# DA1470x register map
Vendor: Dialog; Series: DA1470x; File version: 1.2
CPU: CM33 r0p2, little endian, MPU, FPU, DSP, VTOR, 4 interrupt priority bits
Registers are 32-bit, read-write, reset 0x0 unless marked. A register's access mark holds for its fields unless they carry their own. Offsets are from the block's base; [hi:lo] are bit positions.

## CRG_VSYS — CRG_VSYS registers
Base 0x50000B00
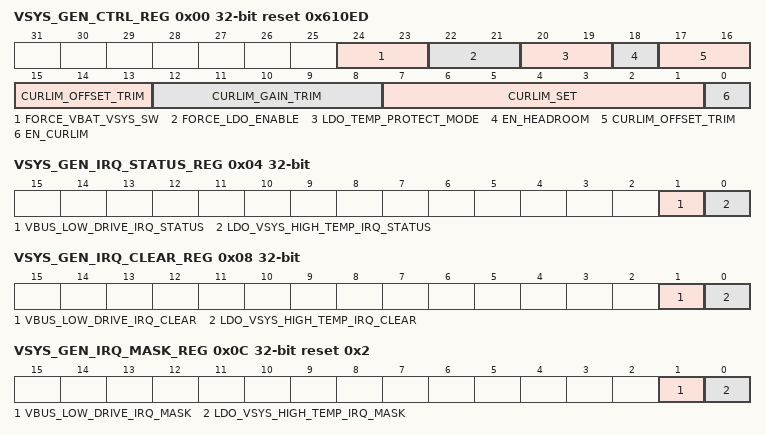
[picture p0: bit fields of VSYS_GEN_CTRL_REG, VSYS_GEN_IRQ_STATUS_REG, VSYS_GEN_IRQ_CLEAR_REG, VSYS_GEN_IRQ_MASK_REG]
0x00 VSYS_GEN_CTRL_REG reset 0x610ED
  [24:23] FORCE_VBAT_VSYS_SW — 0x0,0x1: VBAT_VSYS set to ideal diode 0x2: Forces VBAT_VSYS switch to be opened 0x3: Forces VBAT_VSYS switch to be closed
  [22:21] FORCE_LDO_ENABLE — 0x0,0x1: LDO VSYS will be enabled when COMP_VBUS_OK & COMP_VBUS_ABOVE_VSYS. 0x2: LDO_VSYS will be disabled regardless of VBUS state 0x3: LDO_VSYS will be enabled regardless of VBUS state
  [20:19] LDO_TEMP_PROTECT_MODE — 0x0: LDO_VSYS is muted (disabled) when temperature is too high, when temperature is back to operating conditions ldo is unmuted 0x1: LDO_VSYS is muted (disabled) when temperature is too high, LDO_VSYS_HIGH_TEMP_IRQ must be cleared to allow ldo to be unmuted. See VSYS_GEN_IRQ_CLEAR_REG. 0x2: LDO_VSYS is not muted (disabled) when temperature is too high 0x3: Force LDO_VSYS mute
  [18] EN_HEADROOM — Enables the voltage headroom loop in the LDO_VSYS.
  [17:13] CURLIM_OFFSET_TRIM — For adjusting the offset of the curlim range ( +/- 78 mA) 0x0 = maximum positive offset. 0x10 = minimal offset ( reset value). 0x1F = maximum negative offset.
  [12:8] CURLIM_GAIN_TRIM — For adjusting the gain of the curlim range ( +/- 20%) 0x0 = maximum gain. 0x10 = nominal gain ( reset value). 0x1F = minimum gain.
  [7:1] CURLIM_SET — Sets the level of the LDO_VSYS current limiter in 10 mA steps. It is reset when vbus is not plugged (COMP_VBUS_PLUGIN == 0). 0x0 = 1270 mA 0x1 = 1260 mA ... 0x76 = 90 mA ( reset value)
  [0] EN_CURLIM — Enables the current limiter in the LDO_VSYS
0x04 VSYS_GEN_IRQ_STATUS_REG
  [1] VBUS_LOW_DRIVE_IRQ_STATUS — Indicates vbus drive strength is not enough to keep vbus up with the set limit of ldo_vbus. Consider lowering CURLIM_SET in VSYS_GEN_CTRL_REG.
  [0] LDO_VSYS_HIGH_TEMP_IRQ_STATUS — Indicates that a high temperature has been detected at ldo_vsys
0x08 VSYS_GEN_IRQ_CLEAR_REG
  [1] VBUS_LOW_DRIVE_IRQ_CLEAR wo — Clears VBUS_LOW_DRIVE_IRQ
  [0] LDO_VSYS_HIGH_TEMP_IRQ_CLEAR wo — Clears LDO_VSYS_HIGH_TEMP_IRQ
0x0C VSYS_GEN_IRQ_MASK_REG reset 0x2
  [1] VBUS_LOW_DRIVE_IRQ_MASK — Masks VBUS_LOW_DRIVE_IRQ interrupt. It is reset when vbus is not plugged in (COMP_VBUS_PLUGIN == 0). This is because when vbus is just plugged in, it is likely to bounce; therefore IRQ is masked to avoid false triggering. Some time after vbus plugin, software might increase ldo_vsys current limit and should set this mask to 0 (after clearing IRQ).
  [0] LDO_VSYS_HIGH_TEMP_IRQ_MASK — Masks LDO_VSYS_HIGH_TEMP_IRQ interrupt

## DCDC — DCDC registers
Base 0x50000300
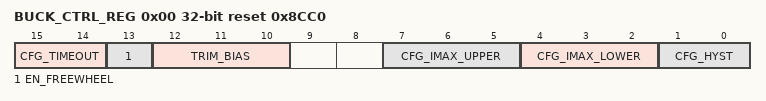
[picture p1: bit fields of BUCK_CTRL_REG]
0x00 BUCK_CTRL_REG reset 0x8CC0
  [15:14] CFG_TIMEOUT — Sets maximum switch on-time. 0x0: Disabled 0x1: 0.5 ms 0x2: 1.0 ms (Default) 0x3: 1.5 ms
  [13] EN_FREEWHEEL — Enables freewheel switch when converter is idle.
  [12:10] TRIM_BIAS — Bias current trim. 0x0: -21 % 0x1: -14 % 0x2: -7 % 0x3: +0 % (Default) 0x4: +7 % 0x5: +14 % 0x6: +21 % 0x7: +28 %
  [7:5] CFG_IMAX_UPPER — Sets upper value of inductor peak current limit control. 0x0: 260 mA 0x1: 400 mA 0x2: 530 mA 0x3: 660 mA 0x4: 790 mA 0x5: 920 mA 0x6: 1060 mA (Default) 0x7: 1190 mA
  [4:2] CFG_IMAX_LOWER — Sets lower value of inductor peak current limit control. 0x0: 260 mA (Default) 0x1: 400 mA 0x2: 530 mA 0x3: 660 mA 0x4: 790 mA 0x5: 920 mA 0x6: 1060 mA 0x7: 1190 mA
  [1:0] CFG_HYST — Controls hysteresis on output comparator. Values listed are typical. 0x0: 6 mV (Default) 0x1: 9 mV 0x2: 12 mV 0x3: 15 mV

## GPU_REG — GPU_REG registers
Base 0x51001100
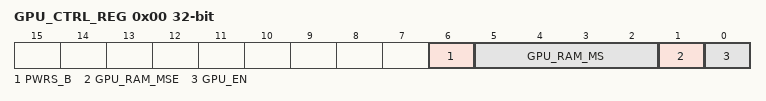
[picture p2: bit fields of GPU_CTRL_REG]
0x00 GPU_CTRL_REG
  [6] PWRS_B — Power save mode read port memories 0: Disabled 1: Enabled
  [5:2] GPU_RAM_MS — Margin setting for GPU memories
  [1] GPU_RAM_MSE — Margin enable for GPU memories
  [0] GPU_EN — GPU enable 0:Enable 1:Disable
